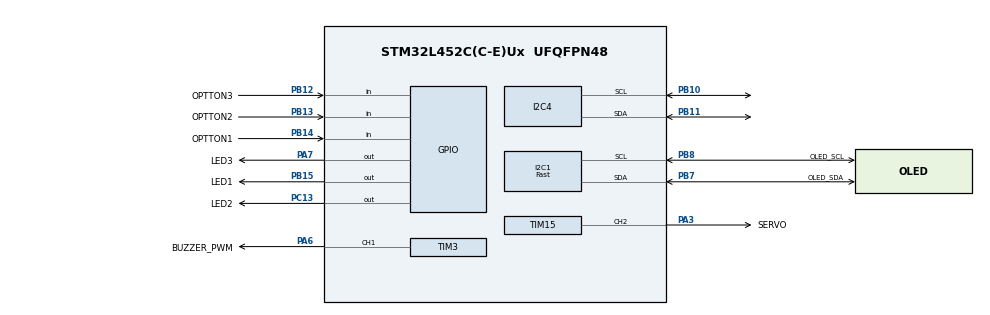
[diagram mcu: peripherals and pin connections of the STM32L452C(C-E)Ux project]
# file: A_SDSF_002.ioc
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I2C1.I2C_Speed_Mode=I2C_Fast
I2C1.Timing=0x00000003
I2C4.Timing=0x00100D14
Mcu.Family=STM32L4
Mcu.Name=STM32L452C(C-E)Ux
Mcu.Package=UFQFPN48
NVIC.PriorityGroup=NVIC_PRIORITYGROUP_4
PA3.GPIO_Label=SERVO
PA3.Signal=S_TIM15_CH2
PA6.GPIO_Label=BUZZER_PWM
PA6.Signal=S_TIM3_CH1
PA7.GPIO_Label=LED3
PA7.Signal=GPIO_Output
PB10.Mode=I2C
PB10.Signal=I2C4_SCL
PB11.Mode=I2C
PB11.Signal=I2C4_SDA
PB12.GPIO_Label=OPTTON3
PB12.Signal=GPIO_Input
PB13.GPIO_Label=OPTTON2
PB13.Signal=GPIO_Input
PB14.GPIO_Label=OPTTON1
PB14.Signal=GPIO_Input
PB15.GPIO_Label=LED1
PB15.Signal=GPIO_Output
PB7.GPIO_Label=OLED_SDA
PB7.Mode=I2C
PB7.Signal=I2C1_SDA
PB8.GPIO_Label=OLED_SCL
PB8.Mode=I2C
PB8.Signal=I2C1_SCL
PC13.GPIO_Label=LED2
PC13.Signal=GPIO_Output
ProjectManager.HeapSize=0x200
ProjectManager.StackSize=0x400
ProjectManager.TargetToolchain=STM32CubeIDE
RCC.HSE_VALUE=8000000
RCC.HSI48_VALUE=48000000
RCC.HSI_VALUE=16000000
RCC.LSE_VALUE=32768
RCC.MSI_VALUE=4000000
RCC.VCOOutputFreq_Value=32000000
SH.S_TIM15_CH2.0=TIM15_CH2,PWM Generation2 CH2
SH.S_TIM3_CH1.0=TIM3_CH1,PWM Generation1 CH1
TIM15.Channel-PWM\ Generation2\ CH2=TIM_CHANNEL_2
TIM15.Period=20000-1
TIM15.Prescaler=4-1
TIM15.Pulse-PWM\ Generation2\ CH2=1000
TIM3.Channel-PWM\ Generation1\ CH1=TIM_CHANNEL_1
TIM3.Period=99
TIM3.Prescaler=9
TIM3.Pulse-PWM\ Generation1\ CH1=50
VP_TIM15_VS_ClockSourceINT.Mode=Internal
board=custom

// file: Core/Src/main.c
/* USER CODE BEGIN Header */
/**
 ******************************************************************************
 * @file           : main.c
 * @brief          : Main program body
 ******************************************************************************
 * @attention
 *
 * Copyright (c) 2024 STMicroelectronics.
 * All rights reserved.
 *
 * This software is licensed under terms that can be found in the LICENSE file
 * in the root directory of this software component.
 * If no LICENSE file comes with this software, it is provided AS-IS.
 *
 ******************************************************************************
 */
/* USER CODE END Header */
#include "main.h"

/* USER CODE BEGIN Includes */
#include "display.h"
#include "sensors.h"
#include "state_machine.h"
/* USER CODE END Includes */

I2C_HandleTypeDef hi2c1;
I2C_HandleTypeDef hi2c4;

TIM_HandleTypeDef htim3;
TIM_HandleTypeDef htim15;

void SystemClock_Config(void);
static void MX_GPIO_Init(void);
static void MX_I2C1_Init(void);
static void MX_I2C4_Init(void);
static void MX_TIM15_Init(void);
static void MX_TIM3_Init(void);

int main(void)
{

  /* MCU Configuration--------------------------------------------------------*/

  /* Reset of all peripherals, Initializes the Flash interface and the Systick. */
  HAL_Init();

  /* Configure the system clock */
  SystemClock_Config();

  /* Initialize all configured peripherals */
  MX_GPIO_Init();
  MX_I2C1_Init();
  MX_I2C4_Init();
  MX_TIM15_Init();
  MX_TIM3_Init();
  /* USER CODE BEGIN 2 */
	Oled_Init();
	Servo_Init(&htim15);
	StateMc_Init(&htim15);
	HAL_Delay(500);
	Oled_Clear();

  /* USER CODE END 2 */

  /* Infinite loop */
	while (1) {

    /* USER CODE BEGIN 3 */
		stateRunning();
	}
  /* USER CODE END 3 */
}

void SystemClock_Config(void)
{
  RCC_OscInitTypeDef RCC_OscInitStruct = {0};
  RCC_ClkInitTypeDef RCC_ClkInitStruct = {0};

  /** Configure the main internal regulator output voltage
  */
  if (HAL_PWREx_ControlVoltageScaling(PWR_REGULATOR_VOLTAGE_SCALE1) != HAL_OK)
  {
    Error_Handler();
  }

  /** Initializes the RCC Oscillators according to the specified parameters
  * in the RCC_OscInitTypeDef structure.
  */
  RCC_OscInitStruct.OscillatorType = RCC_OSCILLATORTYPE_MSI;
  RCC_OscInitStruct.MSIState = RCC_MSI_ON;
  RCC_OscInitStruct.MSICalibrationValue = 0;
  RCC_OscInitStruct.MSIClockRange = RCC_MSIRANGE_6;
  RCC_OscInitStruct.PLL.PLLState = RCC_PLL_NONE;
  if (HAL_RCC_OscConfig(&RCC_OscInitStruct) != HAL_OK)
  {
    Error_Handler();
  }

  /** Initializes the CPU, AHB and APB buses clocks
  */
  RCC_ClkInitStruct.ClockType = RCC_CLOCKTYPE_HCLK|RCC_CLOCKTYPE_SYSCLK
                              |RCC_CLOCKTYPE_PCLK1|RCC_CLOCKTYPE_PCLK2;
  RCC_ClkInitStruct.SYSCLKSource = RCC_SYSCLKSOURCE_MSI;
  RCC_ClkInitStruct.AHBCLKDivider = RCC_SYSCLK_DIV1;
  RCC_ClkInitStruct.APB1CLKDivider = RCC_HCLK_DIV1;
  RCC_ClkInitStruct.APB2CLKDivider = RCC_HCLK_DIV1;

  if (HAL_RCC_ClockConfig(&RCC_ClkInitStruct, FLASH_LATENCY_0) != HAL_OK)
  {
    Error_Handler();
  }
}

static void MX_I2C1_Init(void)
{

  hi2c1.Instance = I2C1;
  hi2c1.Init.Timing = 0x00000003;
  hi2c1.Init.OwnAddress1 = 0;
  hi2c1.Init.AddressingMode = I2C_ADDRESSINGMODE_7BIT;
  hi2c1.Init.DualAddressMode = I2C_DUALADDRESS_DISABLE;
  hi2c1.Init.OwnAddress2 = 0;
  hi2c1.Init.OwnAddress2Masks = I2C_OA2_NOMASK;
  hi2c1.Init.GeneralCallMode = I2C_GENERALCALL_DISABLE;
  hi2c1.Init.NoStretchMode = I2C_NOSTRETCH_DISABLE;
  if (HAL_I2C_Init(&hi2c1) != HAL_OK)
  {
    Error_Handler();
  }

  /** Configure Analogue filter
  */
  if (HAL_I2CEx_ConfigAnalogFilter(&hi2c1, I2C_ANALOGFILTER_ENABLE) != HAL_OK)
  {
    Error_Handler();
  }

  /** Configure Digital filter
  */
  if (HAL_I2CEx_ConfigDigitalFilter(&hi2c1, 0) != HAL_OK)
  {
    Error_Handler();
  }

}

static void MX_I2C4_Init(void)
{

  hi2c4.Instance = I2C4;
  hi2c4.Init.Timing = 0x00100D14;
  hi2c4.Init.OwnAddress1 = 0;
  hi2c4.Init.AddressingMode = I2C_ADDRESSINGMODE_7BIT;
  hi2c4.Init.DualAddressMode = I2C_DUALADDRESS_DISABLE;
  hi2c4.Init.OwnAddress2 = 0;
  hi2c4.Init.OwnAddress2Masks = I2C_OA2_NOMASK;
  hi2c4.Init.GeneralCallMode = I2C_GENERALCALL_DISABLE;
  hi2c4.Init.NoStretchMode = I2C_NOSTRETCH_DISABLE;
  if (HAL_I2C_Init(&hi2c4) != HAL_OK)
  {
    Error_Handler();
  }

  /** Configure Analogue filter
  */
  if (HAL_I2CEx_ConfigAnalogFilter(&hi2c4, I2C_ANALOGFILTER_ENABLE) != HAL_OK)
  {
    Error_Handler();
  }

  /** Configure Digital filter
  */
  if (HAL_I2CEx_ConfigDigitalFilter(&hi2c4, 0) != HAL_OK)
  {
    Error_Handler();
  }

}

static void MX_TIM3_Init(void)
{

  TIM_MasterConfigTypeDef sMasterConfig = {0};
  TIM_OC_InitTypeDef sConfigOC = {0};

  htim3.Instance = TIM3;
  htim3.Init.Prescaler = 9;
  htim3.Init.CounterMode = TIM_COUNTERMODE_UP;
  htim3.Init.Period = 99;
  htim3.Init.ClockDivision = TIM_CLOCKDIVISION_DIV1;
  htim3.Init.AutoReloadPreload = TIM_AUTORELOAD_PRELOAD_DISABLE;
  if (HAL_TIM_PWM_Init(&htim3) != HAL_OK)
  {
    Error_Handler();
  }
  sMasterConfig.MasterOutputTrigger = TIM_TRGO_RESET;
  sMasterConfig.MasterSlaveMode = TIM_MASTERSLAVEMODE_DISABLE;
  if (HAL_TIMEx_MasterConfigSynchronization(&htim3, &sMasterConfig) != HAL_OK)
  {
    Error_Handler();
  }
  sConfigOC.OCMode = TIM_OCMODE_PWM1;
  sConfigOC.Pulse = 50;
  sConfigOC.OCPolarity = TIM_OCPOLARITY_HIGH;
  sConfigOC.OCFastMode = TIM_OCFAST_DISABLE;
  if (HAL_TIM_PWM_ConfigChannel(&htim3, &sConfigOC, TIM_CHANNEL_1) != HAL_OK)
  {
    Error_Handler();
  }
  HAL_TIM_MspPostInit(&htim3);

}

static void MX_TIM15_Init(void)
{

  TIM_ClockConfigTypeDef sClockSourceConfig = {0};
  TIM_MasterConfigTypeDef sMasterConfig = {0};
  TIM_OC_InitTypeDef sConfigOC = {0};
  TIM_BreakDeadTimeConfigTypeDef sBreakDeadTimeConfig = {0};

  htim15.Instance = TIM15;
  htim15.Init.Prescaler = 4-1;
  htim15.Init.CounterMode = TIM_COUNTERMODE_UP;
  htim15.Init.Period = 20000-1;
  htim15.Init.ClockDivision = TIM_CLOCKDIVISION_DIV1;
  htim15.Init.RepetitionCounter = 0;
  htim15.Init.AutoReloadPreload = TIM_AUTORELOAD_PRELOAD_DISABLE;
  if (HAL_TIM_Base_Init(&htim15) != HAL_OK)
  {
    Error_Handler();
  }
  sClockSourceConfig.ClockSource = TIM_CLOCKSOURCE_INTERNAL;
  if (HAL_TIM_ConfigClockSource(&htim15, &sClockSourceConfig) != HAL_OK)
  {
    Error_Handler();
  }
  if (HAL_TIM_PWM_Init(&htim15) != HAL_OK)
  {
    Error_Handler();
  }
  sMasterConfig.MasterOutputTrigger = TIM_TRGO_RESET;
  sMasterConfig.MasterSlaveMode = TIM_MASTERSLAVEMODE_DISABLE;
  if (HAL_TIMEx_MasterConfigSynchronization(&htim15, &sMasterConfig) != HAL_OK)
  {
    Error_Handler();
  }
  sConfigOC.OCMode = TIM_OCMODE_PWM1;
  sConfigOC.Pulse = 1000;
  sConfigOC.OCPolarity = TIM_OCPOLARITY_HIGH;
  sConfigOC.OCNPolarity = TIM_OCNPOLARITY_HIGH;
  sConfigOC.OCFastMode = TIM_OCFAST_DISABLE;
  sConfigOC.OCIdleState = TIM_OCIDLESTATE_RESET;
  sConfigOC.OCNIdleState = TIM_OCNIDLESTATE_RESET;
  if (HAL_TIM_PWM_ConfigChannel(&htim15, &sConfigOC, TIM_CHANNEL_2) != HAL_OK)
  {
    Error_Handler();
  }
  sBreakDeadTimeConfig.OffStateRunMode = TIM_OSSR_DISABLE;
  sBreakDeadTimeConfig.OffStateIDLEMode = TIM_OSSI_DISABLE;
  sBreakDeadTimeConfig.LockLevel = TIM_LOCKLEVEL_OFF;
  sBreakDeadTimeConfig.DeadTime = 0;
  sBreakDeadTimeConfig.BreakState = TIM_BREAK_DISABLE;
  sBreakDeadTimeConfig.BreakPolarity = TIM_BREAKPOLARITY_HIGH;
  sBreakDeadTimeConfig.AutomaticOutput = TIM_AUTOMATICOUTPUT_DISABLE;
  if (HAL_TIMEx_ConfigBreakDeadTime(&htim15, &sBreakDeadTimeConfig) != HAL_OK)
  {
    Error_Handler();
  }
  HAL_TIM_MspPostInit(&htim15);

}

static void MX_GPIO_Init(void)
{
  GPIO_InitTypeDef GPIO_InitStruct = {0};

  /* GPIO Ports Clock Enable */
  __HAL_RCC_GPIOC_CLK_ENABLE();
  __HAL_RCC_GPIOA_CLK_ENABLE();
  __HAL_RCC_GPIOB_CLK_ENABLE();

  /*Configure GPIO pin Output Level */
  HAL_GPIO_WritePin(LED2_GPIO_Port, LED2_Pin, GPIO_PIN_RESET);

  /*Configure GPIO pin Output Level */
  HAL_GPIO_WritePin(LED3_GPIO_Port, LED3_Pin, GPIO_PIN_RESET);

  /*Configure GPIO pin Output Level */
  HAL_GPIO_WritePin(LED1_GPIO_Port, LED1_Pin, GPIO_PIN_RESET);

  /*Configure GPIO pin : LED2_Pin */
  GPIO_InitStruct.Pin = LED2_Pin;
  GPIO_InitStruct.Mode = GPIO_MODE_OUTPUT_PP;
  GPIO_InitStruct.Pull = GPIO_NOPULL;
  GPIO_InitStruct.Speed = GPIO_SPEED_FREQ_LOW;
  HAL_GPIO_Init(LED2_GPIO_Port, &GPIO_InitStruct);

  /*Configure GPIO pin : LED3_Pin */
  GPIO_InitStruct.Pin = LED3_Pin;
  GPIO_InitStruct.Mode = GPIO_MODE_OUTPUT_PP;
  GPIO_InitStruct.Pull = GPIO_NOPULL;
  GPIO_InitStruct.Speed = GPIO_SPEED_FREQ_LOW;
  HAL_GPIO_Init(LED3_GPIO_Port, &GPIO_InitStruct);

  /*Configure GPIO pins : OPTTON3_Pin OPTTON2_Pin OPTTON1_Pin */
  GPIO_InitStruct.Pin = OPTTON3_Pin|OPTTON2_Pin|OPTTON1_Pin;
  GPIO_InitStruct.Mode = GPIO_MODE_INPUT;
  GPIO_InitStruct.Pull = GPIO_NOPULL;
  HAL_GPIO_Init(GPIOB, &GPIO_InitStruct);

  /*Configure GPIO pin : LED1_Pin */
  GPIO_InitStruct.Pin = LED1_Pin;
  GPIO_InitStruct.Mode = GPIO_MODE_OUTPUT_PP;
  GPIO_InitStruct.Pull = GPIO_NOPULL;
  GPIO_InitStruct.Speed = GPIO_SPEED_FREQ_LOW;
  HAL_GPIO_Init(LED1_GPIO_Port, &GPIO_InitStruct);

}

void Error_Handler(void)
{
	__disable_irq();
	while (1) {
	}
}
